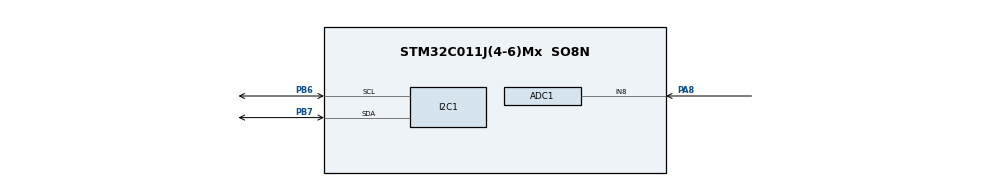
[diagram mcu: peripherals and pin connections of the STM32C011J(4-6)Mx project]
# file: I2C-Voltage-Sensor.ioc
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ADC1.NbrOfConversionFlag=0
ADC1.SamplingTimeCommon1=ADC_SAMPLETIME_79CYCLES_5
ADC1.SelectedChannel=ADC_CHANNEL_8
ADC1.master=1
I2C1.Analog_Filter=I2C_ANALOGFILTER_ENABLE
I2C1.OwnAddress=36
I2C1.Timing=0x00402D41
Mcu.Family=STM32C0
Mcu.Name=STM32C011J(4-6)Mx
Mcu.Package=SO8N
NVIC.I2C1_IRQn=true\:0\:0\:false\:false\:true\:true\:true\:true
PA8.Mode=IN8
PA8.Signal=ADC1_IN8
PA8__PA11\ [PA9].StandardMode=true
PB6.Mode=I2C
PB6.Signal=I2C1_SCL
PB7.Mode=I2C
PB7.Signal=I2C1_SDA
PC14-OSCX_IN\ (PC14)__PB7.StandardMode=true
PC15-OSCX_OUT\ (PC15)__PA14-BOOT0__PB6.StandardMode=true
PF2-NRST__PA0__PA1__PA2.StandardMode=true
ProjectManager.HeapSize=0x200
ProjectManager.StackSize=0x400
ProjectManager.TargetToolchain=STM32CubeIDE
RCC.ADCFreq_Value=12000000
RCC.AHBFreq_Value=12000000
RCC.CortexFreq_Value=12000000
RCC.EXTERNAL_CLOCK_VALUE=12288000
RCC.HCLKFreq_Value=12000000
RCC.HSE_VALUE=8000000
RCC.HSI_VALUE=48000000
RCC.LSE_VALUE=32768
RCC.SYSCLKFreq_VALUE=12000000
board=custom

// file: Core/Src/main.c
/* USER CODE BEGIN Header */
/**
 ******************************************************************************
 * @file           : main.c
 * @brief          : Main program body
 ******************************************************************************
 * @attention
 *
 * Copyright (c) 2025 STMicroelectronics.
 * All rights reserved.
 *
 * This software is licensed under terms that can be found in the LICENSE file
 * in the root directory of this software component.
 * If no LICENSE file comes with this software, it is provided AS-IS.
 *
 ******************************************************************************
 */
/* USER CODE END Header */
#include "main.h"

/* USER CODE BEGIN Includes */
#include "i2c_slave.h"

/* USER CODE END Includes */

/* USER CODE BEGIN PD */
#define CALIBRATION_FLASH_ADDR (0x08007C00) // Last page in flash

/* USER CODE END PD */

ADC_HandleTypeDef hadc1;

I2C_HandleTypeDef hi2c1;

/* USER CODE BEGIN PV */
uint32_t adc_offset_mv = 0; // Loaded from flash at startup

/* USER CODE END PV */

void SystemClock_Config(void);
static void MX_GPIO_Init(void);
static void MX_ADC1_Init(void);
static void MX_I2C1_Init(void);

/* USER CODE BEGIN 0 */

void save_calibration_to_flash(uint32_t offset)
{

  HAL_FLASH_Unlock();

  // Erase page
  FLASH_EraseInitTypeDef erase;
  erase.TypeErase = FLASH_TYPEERASE_PAGES;
  erase.Page = (CALIBRATION_FLASH_ADDR - 0x08000000) / FLASH_PAGE_SIZE;
  erase.NbPages = 1;

  uint32_t error;
  HAL_FLASHEx_Erase(&erase, &error);

  // Write new data
  uint64_t data64 = offset;
  HAL_FLASH_Program(FLASH_TYPEPROGRAM_DOUBLEWORD, CALIBRATION_FLASH_ADDR, data64);

  HAL_FLASH_Lock();
}

void calibrate_ADC_offset(void)
{
  uint32_t sum = 0;
  const int samples = 64;

  for (int i = 0; i < samples; i++)
  {
    HAL_ADC_Start(&hadc1);
    HAL_ADC_PollForConversion(&hadc1, 10);
    sum += HAL_ADC_GetValue(&hadc1);
    HAL_ADC_Stop(&hadc1);
    HAL_Delay(2);
  }

  uint32_t avg = sum / samples;

  uint32_t vin_mv = (uint32_t)((uint64_t)avg * 3300ULL * 57ULL / (4095ULL * 10ULL));

  adc_offset_mv = vin_mv;

  save_calibration_to_flash(adc_offset_mv);
}

void load_calibration(void)
{
  uint64_t raw = *(uint64_t *)CALIBRATION_FLASH_ADDR;
  uint32_t val = (uint32_t)(raw & 0xFFFFFFFF);

  if (val != 0xFFFFFFFF) // flash empty?
    adc_offset_mv = val;
  else
    adc_offset_mv = 0; // no calibration yet
}

/* USER CODE END 0 */

int main(void)
{

  /* MCU Configuration--------------------------------------------------------*/

  /* Reset of all peripherals, Initializes the Flash interface and the Systick. */
  HAL_Init();

  /* Configure the system clock */
  SystemClock_Config();

  /* USER CODE BEGIN SysInit */
  //__HAL_RCC_SYSCFG_CLK_ENABLE();
  // MODIFY_REG(SYSCFG->CFGR3, (3U << 0), 0U);   // PINMUX0[1:0] = 00 -> PB7 active

  /* USER CODE END SysInit */

  /* Initialize all configured peripherals */
  MX_GPIO_Init();
  MX_ADC1_Init();
  MX_I2C1_Init();
  /* USER CODE BEGIN 2 */
  I2C_Slave_Init();
  load_calibration();

  /* USER CODE END 2 */

  /* Infinite loop */
  while (1)
  {

    /* USER CODE BEGIN 3 */
    if (i2c_calibration_request)
    {
      i2c_calibration_request = 0;
      i2c_conversion_busy = 1;

      calibrate_ADC_offset();

      i2c_conversion_busy = 0;
    }

    if (i2c_conversion_request)
    {
      i2c_conversion_request = 0;
      i2c_conversion_busy = 1;
      i2c_data_ready = 0;

      // Preform ADC averaging
      uint32_t sum = 0;
      const uint32_t samples = 50;

      for (uint32_t i = 0; i < samples; i++)
      {
        if (HAL_ADC_Start(&hadc1) != HAL_OK)
        {
          break;
        }

        if (HAL_ADC_PollForConversion(&hadc1, 10) == HAL_OK)
        {
          sum += HAL_ADC_GetValue(&hadc1);
        }

        HAL_ADC_Stop(&hadc1);
        HAL_Delay(1); // Small delay between samples
      }

      uint16_t avg = (uint16_t)(sum / samples);

      /* convert ADC average to input voltage (mV)
      ADC_ref = 3.3V -> 3300 mV
      divider inverse = 1 / 0.175438596 = 5.7 = 57/10
      Vin_mV = avg * 3300 * 5.7 / 4095
      use 64-bit intermediate to avoid overflow
      */
      uint32_t vin_mv = (uint32_t)((uint64_t)avg * 3300ULL * 57ULL / (4095ULL * 10ULL));

      // Subtract constant offset of 693mV
      if (vin_mv > adc_offset_mv)
        vin_mv -= adc_offset_mv;
      else
        vin_mv = 0;

      // 16-bit clamp
      if (vin_mv > 0xFFFFU)
      {
        vin_mv = 0xFFFFU;
      }

      /* prepare transmit buffer (MSB first) */
      // Pack result
      i2c_tx_buf[0] = (uint8_t)(vin_mv >> 8);
      i2c_tx_buf[1] = (uint8_t)(vin_mv & 0xFF);

      i2c_data_ready = 1; // Master can now read data
      i2c_conversion_busy = 0;
    }
  }
  /* USER CODE END 3 */
}

void SystemClock_Config(void)
{
  RCC_OscInitTypeDef RCC_OscInitStruct = {0};
  RCC_ClkInitTypeDef RCC_ClkInitStruct = {0};

  __HAL_FLASH_SET_LATENCY(FLASH_LATENCY_0);

  /** Initializes the RCC Oscillators according to the specified parameters
   * in the RCC_OscInitTypeDef structure.
   */
  RCC_OscInitStruct.OscillatorType = RCC_OSCILLATORTYPE_HSI;
  RCC_OscInitStruct.HSIState = RCC_HSI_ON;
  RCC_OscInitStruct.HSIDiv = RCC_HSI_DIV4;
  RCC_OscInitStruct.HSICalibrationValue = RCC_HSICALIBRATION_DEFAULT;
  if (HAL_RCC_OscConfig(&RCC_OscInitStruct) != HAL_OK)
  {
    Error_Handler();
  }

  /** Initializes the CPU, AHB and APB buses clocks
   */
  RCC_ClkInitStruct.ClockType = RCC_CLOCKTYPE_HCLK | RCC_CLOCKTYPE_SYSCLK | RCC_CLOCKTYPE_PCLK1;
  RCC_ClkInitStruct.SYSCLKSource = RCC_SYSCLKSOURCE_HSI;
  RCC_ClkInitStruct.SYSCLKDivider = RCC_SYSCLK_DIV1;
  RCC_ClkInitStruct.AHBCLKDivider = RCC_HCLK_DIV1;
  RCC_ClkInitStruct.APB1CLKDivider = RCC_APB1_DIV1;

  if (HAL_RCC_ClockConfig(&RCC_ClkInitStruct, FLASH_LATENCY_0) != HAL_OK)
  {
    Error_Handler();
  }
}

static void MX_ADC1_Init(void)
{

  ADC_ChannelConfTypeDef sConfig = {0};

  /** Configure the global features of the ADC (Clock, Resolution, Data Alignment and number of conversion)
   */
  hadc1.Instance = ADC1;
  hadc1.Init.ClockPrescaler = ADC_CLOCK_SYNC_PCLK_DIV1;
  hadc1.Init.Resolution = ADC_RESOLUTION_12B;
  hadc1.Init.DataAlign = ADC_DATAALIGN_RIGHT;
  hadc1.Init.ScanConvMode = ADC_SCAN_SEQ_FIXED;
  hadc1.Init.EOCSelection = ADC_EOC_SINGLE_CONV;
  hadc1.Init.LowPowerAutoWait = DISABLE;
  hadc1.Init.LowPowerAutoPowerOff = DISABLE;
  hadc1.Init.ContinuousConvMode = DISABLE;
  hadc1.Init.NbrOfConversion = 1;
  hadc1.Init.DiscontinuousConvMode = DISABLE;
  hadc1.Init.ExternalTrigConv = ADC_SOFTWARE_START;
  hadc1.Init.ExternalTrigConvEdge = ADC_EXTERNALTRIGCONVEDGE_NONE;
  hadc1.Init.DMAContinuousRequests = DISABLE;
  hadc1.Init.Overrun = ADC_OVR_DATA_PRESERVED;
  hadc1.Init.SamplingTimeCommon1 = ADC_SAMPLETIME_79CYCLES_5;
  hadc1.Init.OversamplingMode = DISABLE;
  hadc1.Init.TriggerFrequencyMode = ADC_TRIGGER_FREQ_HIGH;
  if (HAL_ADC_Init(&hadc1) != HAL_OK)
  {
    Error_Handler();
  }

  /** Configure Regular Channel
   */
  sConfig.Channel = ADC_CHANNEL_8;
  sConfig.Rank = ADC_RANK_CHANNEL_NUMBER;
  if (HAL_ADC_ConfigChannel(&hadc1, &sConfig) != HAL_OK)
  {
    Error_Handler();
  }
}

static void MX_I2C1_Init(void)
{

  hi2c1.Instance = I2C1;
  hi2c1.Init.Timing = 0x00402D41;
  hi2c1.Init.OwnAddress1 = 72;
  hi2c1.Init.AddressingMode = I2C_ADDRESSINGMODE_7BIT;
  hi2c1.Init.DualAddressMode = I2C_DUALADDRESS_DISABLE;
  hi2c1.Init.OwnAddress2 = 0;
  hi2c1.Init.OwnAddress2Masks = I2C_OA2_NOMASK;
  hi2c1.Init.GeneralCallMode = I2C_GENERALCALL_DISABLE;
  hi2c1.Init.NoStretchMode = I2C_NOSTRETCH_DISABLE;
  if (HAL_I2C_Init(&hi2c1) != HAL_OK)
  {
    Error_Handler();
  }

  /** Configure Analogue filter
   */
  if (HAL_I2CEx_ConfigAnalogFilter(&hi2c1, I2C_ANALOGFILTER_ENABLE) != HAL_OK)
  {
    Error_Handler();
  }

  /** Configure Digital filter
   */
  if (HAL_I2CEx_ConfigDigitalFilter(&hi2c1, 0) != HAL_OK)
  {
    Error_Handler();
  }
  /* USER CODE BEGIN I2C1_Init 2 */
  HAL_Delay(2); // allow bus to settle
  HAL_I2C_EnableListen_IT(&hi2c1);

  /* USER CODE END I2C1_Init 2 */
}

static void MX_GPIO_Init(void)
{

  /* GPIO Ports Clock Enable */
  __HAL_RCC_GPIOB_CLK_ENABLE();
  __HAL_RCC_GPIOA_CLK_ENABLE();

}

void Error_Handler(void)
{
  __disable_irq();
  while (1)
  {
  }
}
